# S32R372 register map
Vendor: Freescale Semiconductor, Inc.; Series: Qorivva; File version: 1.6
Registers are 32-bit, read-write, reset 0x0 unless marked. A register's access mark holds for its fields unless they carry their own. Offsets are from the block's base; [hi:lo] are bit positions; {n}, {i} and the like mark numbered series.

## TDM
Base 0xFC078000; register names take the prefix TDM_
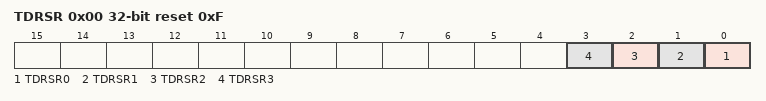
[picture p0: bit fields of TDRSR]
0x00 TDRSR ro reset 0xF — TDR Status Register
  [all] fields
    0=TDR is unlocked. Blocks assigned to this TDR are NOT blocked for erasing by the TDM module. This unlock state is achieved by a successful programming operation to the correct diary region or this TDR has been permanently unlocked by a DCF record that writes to the Tamper Region Override DCF register or a successful software override operation.; 1=TDR is locked. Erase of blocks assigned to this TDR is not possible.
  [n] TDRSR{n} (n=0..3) — Represents the status of TDR {n} in conjunction with the Diary Override Enable status.
0x04 LFPAR ro — Last Flash Programmed Address Register
  [31:0] LFPAR — Last Flash Programmed Address
0x08 DBA ro reset not defined — Diary Base Address
{0x10+4i} STO_KEY{i} (i=0..3) — Software Tamper Override Key Region
  [31:0] STO_KEY — Software Tamper Override Key Diary n

## EIM — Error Injection Module
Base 0xFC07C000; register names take the prefix EIM_
0x00 EIMCR — Error Injection Module Configuration Register
  [0] GEIEN — Global Error Injection Enable
    0=Disabled; 1=Enabled
0x04 EICHEN — Error Injection Channel Enable register
  [31] EICH0EN — Error Injection Channel 0 Enable
    0=Error injection is disabled on Error Injection Channel 0; 1=Error injection is enabled on Error Injection Channel 0
0x100 EICHD_WORD0 — Error Injection Channel Descriptor, Word0
  [31:24] CHKBIT_MASK — Checkbit Mask
    0=The corresponding bit of the checkbit bus remains unmodified; 1=The corresponding bit of the checkbit bus is inverted
0x104 EICHD_WORD1 — Error Injection Channel Descriptor, Word1
  [31:0] B0_3DATA_MASK — Data Mask Bytes 0-3
    0=The corresponding bit of bytes 0-3 on the read data bus remains unmodified; 1=The corresponding bit of bytes 0-3 on the read data bus is inverted
0x108 EICHD_WORD2 — Error Injection Channel Descriptor, Word2
  [31:0] B4_7DATA_MASK — Data Mask Bytes 4-7
    0=The corresponding bit of bytes 4-7 on the read data bus remains unmodified; 1=The corresponding bit of bytes 4-7 on the read data bus is inverted

## DTS
Base 0xFFF38000; register names take the prefix DTS_
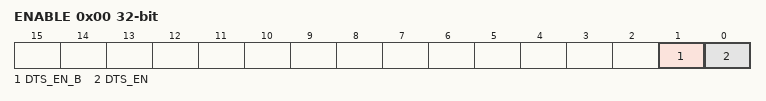
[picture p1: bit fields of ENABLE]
0x00 ENABLE — Output Enable Register
  [1] DTS_EN_B — DTS Enable B
    0=DTS output disabled. Any bit set in the DTS_SEMAPHORE_B register does not assert the DTS trigger output signal.; 1=DTS output enabled. Any bit set in the DTS_SEMAPHORE_B register asserts the DTS trigger output signal (DTO).
  [0] DTS_EN — DTS Enable
    0=DTS output disabled. Any bit set in the DTS_SEMAPHORE register does not assert the DTS trigger output signal.; 1=DTS output enabled. Any bit set in the DTS_SEMAPHORE register asserts the DTS trigger output signal (DTO).
0x04 STARTUP
  [31:0] AD — Application Dependent register bits
0x08 SEMAPHORE reset 0xFFFFFFFF
  [31:0] ST — Semaphore Trigger
    0=No flag; 1=Flag is set
0x0C SEMAPHORE_B reset 0xFFFFFFFF — Semaphore Extension
  [31:0] ST_B — Semaphore Trigger Extension
    0=No flag; 1=Flag is set

## JTAGM
Base 0xFFF48000; register names take the prefix JTAGM_
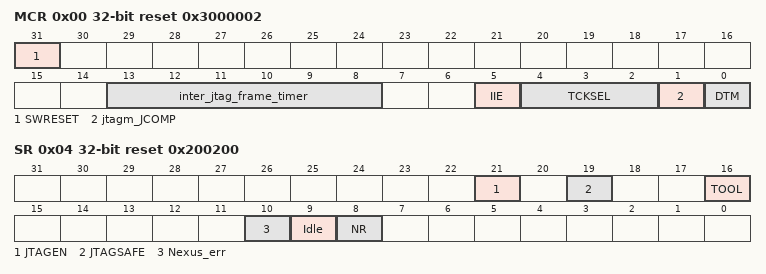
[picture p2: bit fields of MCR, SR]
0x00 MCR reset 0x3000002 — Module Configuration Register
  [31] SWRESET — Software Reset
  [13:8] inter_jtag_frame_timer — TCK delay.
    0=0 TCK delay; 1=1 TCK delay; 63=63 TCK delay
  [5] IIE — Idle Interrupt Enable.
    0=JTAGM does not generate an interrupt to the CPU upon completion of a 60-bit JTAG transfer; 1=JTAGM generates an interrupt to the CPU upon completion of a 60-bit JTAG transfer
  [4:2] TCKSEL — TCK clock frequency selection
    {v}=TCK is system clock * {v+1} (v=2..7)
  [1] jtagm_JCOMP — JTAG reset.
    0=JCOMP low/asserted; 1=JCOMP high/not asserted (default)
  [0] DTM — Data Transfer Mode.
    0=Data transferred by software disabled; 1=Data for JTAG transferred by software
0x04 SR reset 0x200200 — Status Register
  [21] JTAGEN ro — JTAGC status: JTAGC JTAG port enable
  [19] JTAGSAFE ro — JTAGC status: JTAGC JTAG safe mode
  [16] TOOL ro — JTAGC status: JTAGC tool present, set when a debug tool is connected
  [10] Nexus_err ro — Nexus error bit. It is set when there is an error, else it is 0.
  [9] Idle ro — Idle bit
  [8] NR ro — Status of Ready bit from Nexus RWA
    0=RDY has not asserted indicating Nexus RWA is not ready; 1=RDY has asserted indicating a Nexus RWA has completed bus access and is ready for the data register to be read
0x08 DOR0 — Data Out Register 0
  [31:0] TMS_HIGH — Higher word of data for TMS, bits 59-28
0x0C DOR1 — Data Out Register 1
  [31:4] TMS_LOW — Lower word of data for TMS, bits 27-0
0x10 DOR2 — Data Out Register 2
  [31:0] TDI_HIGH — Higher word of data for TDI, bits 59-28
0x14 DOR3 — Data Out Register 3
  [31:4] TDI_LOW — Lower word of data for TDI, bits 27-0
0x1C DIR0 ro — Data Input Register 0
  [31:0] TDO_LOW — Lower word of data received on TDO, bits 0-31
0x20 DIR1 ro — Data Input Register 1
  [31:4] TDO_HIGH — Higher word of data received on TDO, bits 32-59
